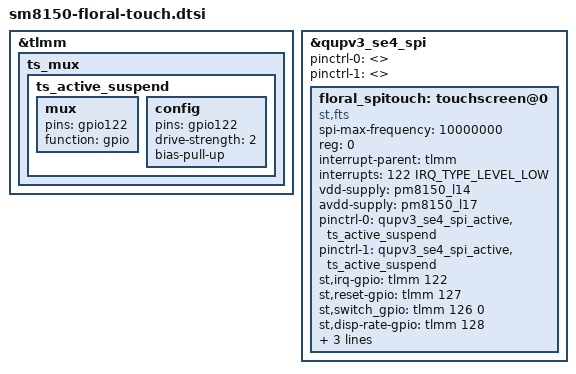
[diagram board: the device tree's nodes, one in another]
/* Copyright (c) 2018, The Linux Foundation. All rights reserved.
 *
 * This program is free software; you can redistribute it and/or modify
 * it under the terms of the GNU General Public License version 2 and
 * only version 2 as published by the Free Software Foundation.
 *
 * This program is distributed in the hope that it will be useful,
 * but WITHOUT ANY WARRANTY; without even the implied warranty of
 * MERCHANTABILITY or FITNESS FOR A PARTICULAR PURPOSE.  See the
 * GNU General Public License for more details.
 */

/* AP Touch SPI CLK is gpio53, CS is gpio54, MISO is gpio51, MOSI is gpio52.
 * Reset gpio127, interrupt gpio122.
 * Bus master switch - gpio126.
 * Display rate - gpio128.
 */

// Keep interrupt pin active at all times
&tlmm {
	ts_mux {
		ts_active_suspend: ts_active_suspend {
			mux {
				pins = "gpio122";
				function = "gpio";
			};
			config {
				pins = "gpio122";
				drive-strength = <2>;
				bias-pull-up;
			};
		};
	};
};

&qupv3_se4_spi {
	status = "ok";
	pinctrl-0 = <>;
	pinctrl-1 = <>;

	floral_spitouch: touchscreen@0 {
		status = "ok";
		compatible = "st,fts";
		spi-max-frequency = <10000000>;

		reg = <0>;
		interrupt-parent = <&tlmm>;
		interrupts = <122 IRQ_TYPE_LEVEL_LOW>;
		vdd-supply = <&pm8150_l14>;
		avdd-supply = <&pm8150_l17>;

		pinctrl-names = "default", "sleep";
		pinctrl-0 = <&qupv3_se4_spi_active &ts_active_suspend>;
		pinctrl-1 = <&qupv3_se4_spi_active &ts_active_suspend>;

		st,irq-gpio = <&tlmm 122 0>;
		st,reset-gpio = <&tlmm 127 0>;
		st,switch_gpio = <&tlmm 126 0>;		// Low: AP, High: SLPI
		st,disp-rate-gpio = <&tlmm 128 0>;
		st,max-coords = <1439 3039>;
		st,regulator_dvdd = "vdd";
		st,regulator_avdd = "avdd";
	};
};

